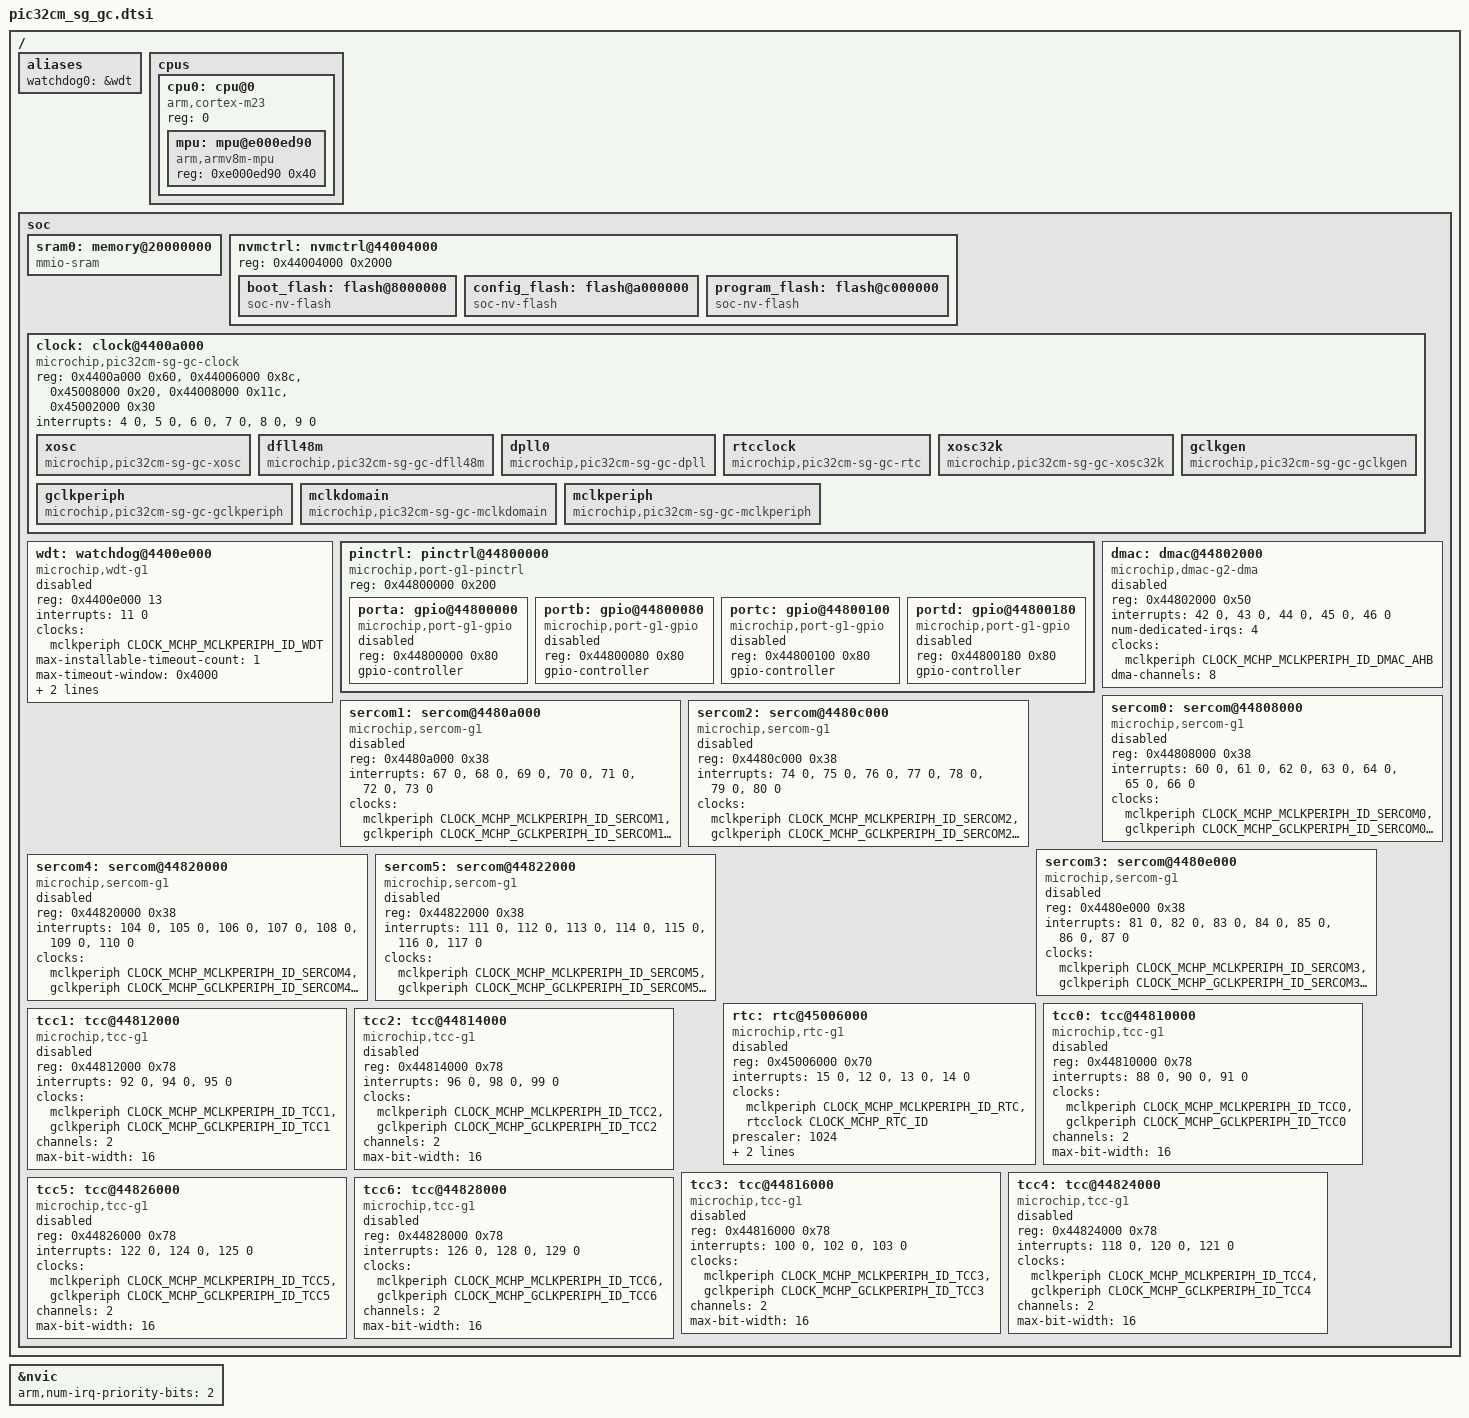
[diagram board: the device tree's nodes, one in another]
/*
 * Copyright (c) 2026 Microchip Technology Inc.
 *
 * SPDX-License-Identifier: Apache-2.0
 */

#include <arm/armv8-m.dtsi>
#include <zephyr/dt-bindings/gpio/gpio.h>
#include <zephyr/dt-bindings/clock/mchp_pic32cm_sg_gc_clock.h>

/ {
	aliases {
		watchdog0 = &wdt;
	};

	cpus {
		#address-cells = <1>;
		#size-cells = <0>;

		cpu0: cpu@0 {
			device_type = "cpu";
			compatible = "arm,cortex-m23";
			reg = <0>;
			#address-cells = <1>;
			#size-cells = <1>;

			mpu: mpu@e000ed90 {
				compatible = "arm,armv8m-mpu";
				reg = <0xe000ed90 0x40>; /* 64 bytes for ARMv8-M MPU */
			};
		};
	};

	soc {
		#address-cells = <1>;
		#size-cells = <1>;

		sram0: memory@20000000 {
			compatible = "mmio-sram";
			#address-cells = <1>;
			#size-cells = <1>;
		};

		nvmctrl: nvmctrl@44004000 {
			reg = <0x44004000 0x2000>;
			#address-cells = <1>;
			#size-cells = <1>;
			ranges;

			boot_flash: flash@8000000 {
				compatible = "soc-nv-flash";
				#address-cells = <1>;
				#size-cells = <1>;
			};

			config_flash: flash@a000000 {
				compatible = "soc-nv-flash";
				#address-cells = <1>;
				#size-cells = <1>;
			};

			program_flash: flash@c000000 {
				compatible = "soc-nv-flash";
				#address-cells = <1>;
				#size-cells = <1>;
			};
		};

		clock: clock@4400a000 {
			compatible = "microchip,pic32cm-sg-gc-clock";
			reg = <0x4400a000 0x60>, <0x44006000 0x8c>,
			      <0x45008000 0x20>, <0x44008000 0x11c>, <0x45002000 0x30>;
			reg-names = "mclk", "oscctrl",
				    "osc32kctrl", "gclk", "supc";
			interrupts = <4 0>, <5 0>, <6 0>,
				     <7 0>, <8 0>, <9 0>;
			interrupt-names = "xosc", "dfll", "pll",
					  "xosc32k-rdy", "xosc32k-fail", "mclk-rdy";

			xosc: xosc {
				compatible = "microchip,pic32cm-sg-gc-xosc";
			};

			dfll48m: dfll48m {
				compatible = "microchip,pic32cm-sg-gc-dfll48m";
			};

			dpll0: dpll0 {
				compatible = "microchip,pic32cm-sg-gc-dpll";
			};

			rtcclock: rtcclock {
				compatible = "microchip,pic32cm-sg-gc-rtc";
				#clock-cells = <1>;
			};

			xosc32k: xosc32k {
				compatible = "microchip,pic32cm-sg-gc-xosc32k";
			};

			gclkgen: gclkgen {
				compatible = "microchip,pic32cm-sg-gc-gclkgen";
			};

			gclkperiph: gclkperiph {
				compatible = "microchip,pic32cm-sg-gc-gclkperiph";
				#clock-cells = <1>;
			};

			mclkdomain: mclkdomain {
				compatible = "microchip,pic32cm-sg-gc-mclkdomain";
			};

			mclkperiph: mclkperiph {
				compatible = "microchip,pic32cm-sg-gc-mclkperiph";
				#clock-cells = <1>;
			};
		};

		wdt: watchdog@4400e000 {
			compatible = "microchip,wdt-g1";
			reg = <0x4400e000 13>;
			interrupts = <11 0>;
			interrupt-names = "wdt-ew";
			clocks = <&mclkperiph CLOCK_MCHP_MCLKPERIPH_ID_WDT>;
			clock-names = "mclk";
			max-installable-timeout-count = <1>;
			max-timeout-window = <0x4000>;
			max-timeout-window-mode = <0x8000>;
			min-window-limit = <0x8>;
			status = "disabled";
		};

		pinctrl: pinctrl@44800000 {
			compatible = "microchip,port-g1-pinctrl";
			#address-cells = <1>;
			#size-cells = <1>;
			reg = <0x44800000 0x200>;
			ranges = <0x44800000 0x44800000 0x200>;

			porta: gpio@44800000 {
				compatible = "microchip,port-g1-gpio";
				reg = <0x44800000 0x80>;
				gpio-controller;
				#gpio-cells = <2>;
				#microchip,pin-cells = <2>;
				status = "disabled";
			};

			portb: gpio@44800080 {
				compatible = "microchip,port-g1-gpio";
				reg = <0x44800080 0x80>;
				gpio-controller;
				#gpio-cells = <2>;
				#microchip,pin-cells = <2>;
				status = "disabled";
			};

			portc: gpio@44800100 {
				compatible = "microchip,port-g1-gpio";
				reg = <0x44800100 0x80>;
				gpio-controller;
				#gpio-cells = <2>;
				#microchip,pin-cells = <2>;
				status = "disabled";
			};

			portd: gpio@44800180 {
				compatible = "microchip,port-g1-gpio";
				reg = <0x44800180 0x80>;
				gpio-controller;
				#gpio-cells = <2>;
				#microchip,pin-cells = <2>;
				status = "disabled";
			};
		};

		dmac: dmac@44802000 {
			compatible = "microchip,dmac-g2-dma";
			reg = <0x44802000 0x50>;
			interrupts = <42 0>, <43 0>, <44 0>, <45 0>, <46 0>;
			interrupt-names = "ch0", "ch1", "ch2", "ch3", "ch4-7";
			num-dedicated-irqs = <4>;
			clocks = <&mclkperiph CLOCK_MCHP_MCLKPERIPH_ID_DMAC_AHB>;
			clock-names = "mclk";
			dma-channels = <8>;
			#dma-cells = <2>;
			status = "disabled";
		};

		sercom0: sercom@44808000 {
			compatible = "microchip,sercom-g1";
			reg = <0x44808000 0x38>;
			interrupts = <60 0>, <61 0>, <62 0>, <63 0>, <64 0>, <65 0>, <66 0>;
			interrupt-names = "error", "rxbrk", "dre", "txc", "rxc", "rxs", "ctsic";
			clocks = <&mclkperiph CLOCK_MCHP_MCLKPERIPH_ID_SERCOM0>,
				 <&gclkperiph CLOCK_MCHP_GCLKPERIPH_ID_SERCOM0_CORE>;
			clock-names = "mclk", "gclk";
			status = "disabled";
		};

		sercom1: sercom@4480a000 {
			compatible = "microchip,sercom-g1";
			reg = <0x4480a000 0x38>;
			interrupts = <67 0>, <68 0>, <69 0>, <70 0>, <71 0>, <72 0>, <73 0>;
			interrupt-names = "error", "rxbrk", "dre", "txc", "rxc", "rxs", "ctsic";
			clocks = <&mclkperiph CLOCK_MCHP_MCLKPERIPH_ID_SERCOM1>,
				 <&gclkperiph CLOCK_MCHP_GCLKPERIPH_ID_SERCOM1_CORE>;
			clock-names = "mclk", "gclk";
			status = "disabled";
		};

		sercom2: sercom@4480c000 {
			compatible = "microchip,sercom-g1";
			reg = <0x4480c000 0x38>;
			interrupts = <74 0>, <75 0>, <76 0>, <77 0>, <78 0>, <79 0>, <80 0>;
			interrupt-names = "error", "rxbrk", "dre", "txc", "rxc", "rxs", "ctsic";
			clocks = <&mclkperiph CLOCK_MCHP_MCLKPERIPH_ID_SERCOM2>,
				 <&gclkperiph CLOCK_MCHP_GCLKPERIPH_ID_SERCOM2_CORE>;
			clock-names = "mclk", "gclk";
			status = "disabled";
		};

		sercom3: sercom@4480e000 {
			compatible = "microchip,sercom-g1";
			reg = <0x4480e000 0x38>;
			interrupts = <81 0>, <82 0>, <83 0>, <84 0>, <85 0>, <86 0>, <87 0>;
			interrupt-names = "error", "rxbrk", "dre", "txc", "rxc", "rxs", "ctsic";
			clocks = <&mclkperiph CLOCK_MCHP_MCLKPERIPH_ID_SERCOM3>,
				 <&gclkperiph CLOCK_MCHP_GCLKPERIPH_ID_SERCOM3_CORE>;
			clock-names = "mclk", "gclk";
			status = "disabled";
		};

		sercom4: sercom@44820000 {
			compatible = "microchip,sercom-g1";
			reg = <0x44820000 0x38>;
			interrupts = <104 0>, <105 0>, <106 0>, <107 0>, <108 0>, <109 0>, <110 0>;
			interrupt-names = "error", "rxbrk", "dre", "txc", "rxc", "rxs", "ctsic";
			clocks = <&mclkperiph CLOCK_MCHP_MCLKPERIPH_ID_SERCOM4>,
				 <&gclkperiph CLOCK_MCHP_GCLKPERIPH_ID_SERCOM4_CORE>;
			clock-names = "mclk", "gclk";
			status = "disabled";
		};

		sercom5: sercom@44822000 {
			compatible = "microchip,sercom-g1";
			reg = <0x44822000 0x38>;
			interrupts = <111 0>, <112 0>, <113 0>, <114 0>, <115 0>, <116 0>, <117 0>;
			interrupt-names = "error", "rxbrk", "dre", "txc", "rxc", "rxs", "ctsic";
			clocks = <&mclkperiph CLOCK_MCHP_MCLKPERIPH_ID_SERCOM5>,
				 <&gclkperiph CLOCK_MCHP_GCLKPERIPH_ID_SERCOM5_CORE>;
			clock-names = "mclk", "gclk";
			status = "disabled";
		};

		rtc: rtc@45006000 {
			compatible = "microchip,rtc-g1";
			reg = <0x45006000 0x70>;
			interrupts = <15 0>, <12 0>, <13 0>, <14 0>;
			interrupt-names = "cmp0-3", "tamper", "ovf", "per0-7";
			clocks = <&mclkperiph CLOCK_MCHP_MCLKPERIPH_ID_RTC>,
				 <&rtcclock CLOCK_MCHP_RTC_ID>;
			clock-names = "mclk", "rtcclk";
			prescaler = <1024>;
			alarms-count = <2>;
			cal-constant = <1048576>;
			status = "disabled";
		};

		tcc0: tcc@44810000 {
			compatible = "microchip,tcc-g1";
			reg = <0x44810000 0x78>;
			interrupts = <88 0>, <90 0>, <91 0>;
			interrupt-names = "other", "mc0", "mc1";
			clocks = <&mclkperiph CLOCK_MCHP_MCLKPERIPH_ID_TCC0>,
				 <&gclkperiph CLOCK_MCHP_GCLKPERIPH_ID_TCC0>;
			clock-names = "mclk", "gclk";
			channels = <2>;
			max-bit-width = <16>;
			status = "disabled";
		};

		tcc1: tcc@44812000 {
			compatible = "microchip,tcc-g1";
			reg = <0x44812000 0x78>;
			interrupts = <92 0>, <94 0>, <95 0>;
			interrupt-names = "other", "mc0", "mc1";
			clocks = <&mclkperiph CLOCK_MCHP_MCLKPERIPH_ID_TCC1>,
				 <&gclkperiph CLOCK_MCHP_GCLKPERIPH_ID_TCC1>;
			clock-names = "mclk", "gclk";
			channels = <2>;
			max-bit-width = <16>;
			status = "disabled";
		};

		tcc2: tcc@44814000 {
			compatible = "microchip,tcc-g1";
			reg = <0x44814000 0x78>;
			interrupts = <96 0>, <98 0>, <99 0>;
			interrupt-names = "other", "mc0", "mc1";
			clocks = <&mclkperiph CLOCK_MCHP_MCLKPERIPH_ID_TCC2>,
				 <&gclkperiph CLOCK_MCHP_GCLKPERIPH_ID_TCC2>;
			clock-names = "mclk", "gclk";
			channels = <2>;
			max-bit-width = <16>;
			status = "disabled";
		};

		tcc3: tcc@44816000 {
			compatible = "microchip,tcc-g1";
			reg = <0x44816000 0x78>;
			interrupts = <100 0>, <102 0>, <103 0>;
			interrupt-names = "other", "mc0", "mc1";
			clocks = <&mclkperiph CLOCK_MCHP_MCLKPERIPH_ID_TCC3>,
				 <&gclkperiph CLOCK_MCHP_GCLKPERIPH_ID_TCC3>;
			clock-names = "mclk", "gclk";
			channels = <2>;
			max-bit-width = <16>;
			status = "disabled";
		};

		tcc4: tcc@44824000 {
			compatible = "microchip,tcc-g1";
			reg = <0x44824000 0x78>;
			interrupts = <118 0>, <120 0>, <121 0>;
			interrupt-names = "other", "mc0", "mc1";
			clocks = <&mclkperiph CLOCK_MCHP_MCLKPERIPH_ID_TCC4>,
				 <&gclkperiph CLOCK_MCHP_GCLKPERIPH_ID_TCC4>;
			clock-names = "mclk", "gclk";
			channels = <2>;
			max-bit-width = <16>;
			status = "disabled";
		};

		tcc5: tcc@44826000 {
			compatible = "microchip,tcc-g1";
			reg = <0x44826000 0x78>;
			interrupts = <122 0>, <124 0>, <125 0>;
			interrupt-names = "other", "mc0", "mc1";
			clocks = <&mclkperiph CLOCK_MCHP_MCLKPERIPH_ID_TCC5>,
				 <&gclkperiph CLOCK_MCHP_GCLKPERIPH_ID_TCC5>;
			clock-names = "mclk", "gclk";
			channels = <2>;
			max-bit-width = <16>;
			status = "disabled";
		};

		tcc6: tcc@44828000 {
			compatible = "microchip,tcc-g1";
			reg = <0x44828000 0x78>;
			interrupts = <126 0>, <128 0>, <129 0>;
			interrupt-names = "other", "mc0", "mc1";
			clocks = <&mclkperiph CLOCK_MCHP_MCLKPERIPH_ID_TCC6>,
				 <&gclkperiph CLOCK_MCHP_GCLKPERIPH_ID_TCC6>;
			clock-names = "mclk", "gclk";
			channels = <2>;
			max-bit-width = <16>;
			status = "disabled";
		};
	};
};

&nvic {
	arm,num-irq-priority-bits = <2>;
};
